# f28p65x_clb_logic_config_regs register map
Vendor: Texas Instruments
Peripheral module from a debugger description file (folder C2000).
Address unit: 16 bits
Registers are 32-bit, read-write, no defined reset value unless marked. A register's access mark holds for its fields unless they carry their own. Offsets are as the file gives them; lines under a group give offsets from that group; [hi:lo] are bit positions; {n}, {i} and the like mark numbered series; 'fields as' and 'values as' point back to an identical list; <NAME> marks a mode.

## CLB_LOGIC_CONFIG_REGS — CLB LOGIC CONFIG Registers
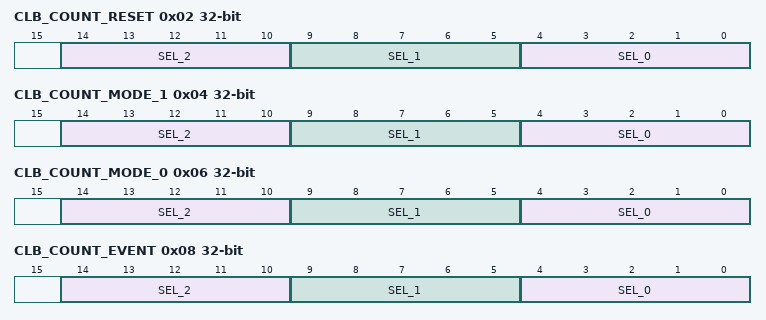
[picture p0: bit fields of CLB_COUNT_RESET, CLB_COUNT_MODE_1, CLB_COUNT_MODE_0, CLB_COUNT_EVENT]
0x02 CLB_COUNT_RESET — Counter Block RESET
  [14:10] SEL_2 — Count Reset Select 2
  [9:5] SEL_1 — Count Reset Select 1
  [4:0] SEL_0 — Count Reset Select 0
0x04 CLB_COUNT_MODE_1 — Counter Block MODE_1
  [14:10] SEL_2 — Counter mode 1 select 2
  [9:5] SEL_1 — Counter mode 1 select 1
  [4:0] SEL_0 — Counter mode 1 select 0
0x06 CLB_COUNT_MODE_0 — Counter Block MODE_0
  [14:10] SEL_2 — Counter mode 0 select 2
  [9:5] SEL_1 — Counter mode 0 select 1
  [4:0] SEL_0 — Counter mode 0 select 0
0x08 CLB_COUNT_EVENT — Counter Block EVENT
  [14:10] SEL_2 — Counter event select 2
  [9:5] SEL_1 — Counter event select 1
  [4:0] SEL_0 — Counter event select 0
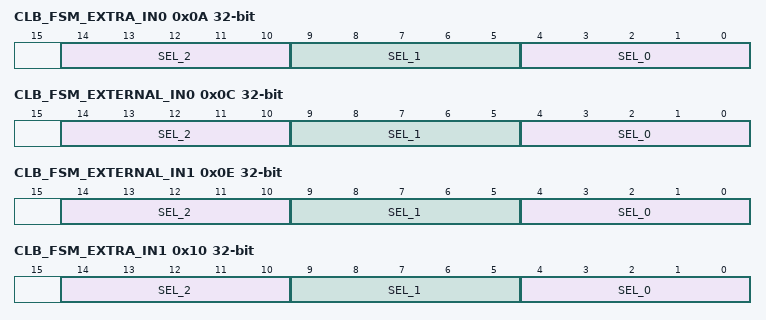
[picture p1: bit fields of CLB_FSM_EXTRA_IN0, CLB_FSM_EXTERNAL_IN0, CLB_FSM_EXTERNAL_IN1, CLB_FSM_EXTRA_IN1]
0x0A CLB_FSM_EXTRA_IN0 — FSM Extra EXT_IN0
  [14:10] SEL_2 — FSM extra ext input select 2
  [9:5] SEL_1 — FSM extra ext input select 1
  [4:0] SEL_0 — FSM extra ext input select 0
0x0C CLB_FSM_EXTERNAL_IN0 — FSM EXT_IN0
  [14:10] SEL_2 — FSM EXT_IN0 select input for unit 2
  [9:5] SEL_1 — FSM EXT_IN0 select input for unit 1
  [4:0] SEL_0 — FSM EXT_IN0 select input for unit 0
0x0E CLB_FSM_EXTERNAL_IN1 — FSM_EXT_IN1
  [14:10] SEL_2 — FSM EXT_IN1 select input for unit 2
  [9:5] SEL_1 — FSM EXT_IN1 select input for unit 1
  [4:0] SEL_0 — FSM EXT_IN1 select input for unit 0
0x10 CLB_FSM_EXTRA_IN1 — FSM Extra_EXT_IN1
  fields as CLB_FSM_EXTRA_IN0
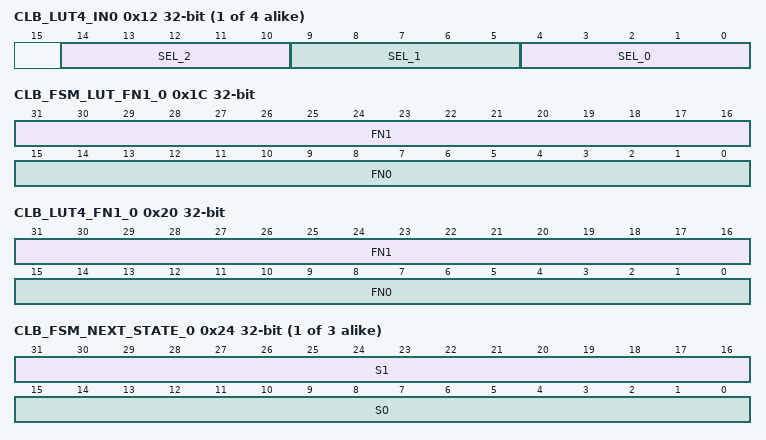
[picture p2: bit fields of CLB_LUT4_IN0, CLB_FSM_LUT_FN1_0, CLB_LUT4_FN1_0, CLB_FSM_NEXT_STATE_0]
{0x12+2i} CLB_LUT4_IN{i} (i=0..3) — LUT4_0/1/2 IN{i} input source
  [14:10] SEL_2 — Select inputs for unit 2
  [9:5] SEL_1 — Select inputs for unit 1
  [4:0] SEL_0 — Select inputs for unit 0
0x1C CLB_FSM_LUT_FN1_0 — LUT function for FSM Unit 1 and Unit 0
  [31:16] FN1 — FSM LUT output function for unit 1
  [15:0] FN0 — FSM LUT output function for unit 0
0x1E CLB_FSM_LUT_FN2 — LUT function for FSM Unit 2
  [15:0] FN1 — FSM LUT output function for unit 2
0x20 CLB_LUT4_FN1_0 — LUT function for LUT4 block of Unit 1 and 0
  [31:16] FN1 — LUT4 output function for unit 1
  [15:0] FN0 — LUT4 output function for unit 0
0x22 CLB_LUT4_FN2 — LUT function for LUT4 block of Unit 2
  [15:0] FN1 — LUT4 output function for unit 2
{0x24+2i} CLB_FSM_NEXT_STATE_{i} (i=0..2) — FSM Next state equations for Unit {i}
  [31:16] S1 — FSM next state function for S1
  [15:0] S0 — FSM next state function for S0
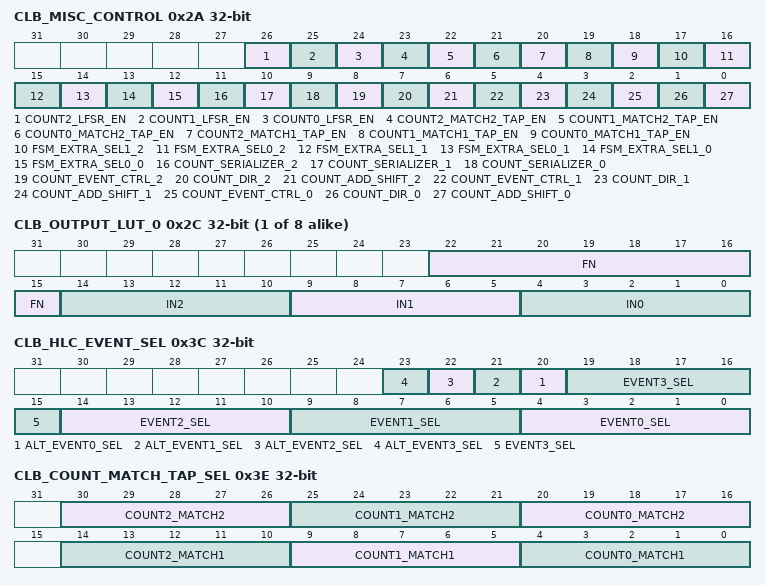
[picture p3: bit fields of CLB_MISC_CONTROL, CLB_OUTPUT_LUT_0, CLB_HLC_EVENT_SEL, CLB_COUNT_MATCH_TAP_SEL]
0x2A CLB_MISC_CONTROL — Static controls for Ctr,FSM
  [26] COUNT2_LFSR_EN — Enable LFSR mode for Counter 2
  [25] COUNT1_LFSR_EN — Enable LFSR mode for Counter 1
  [24] COUNT0_LFSR_EN — Enable LFSR mode for Counter 0
  [23] COUNT2_MATCH2_TAP_EN — Match2 Tap Enable for Counter 2
  [22] COUNT1_MATCH2_TAP_EN — Match2 Tap Enable for Counter 1
  [21] COUNT0_MATCH2_TAP_EN — Match2 Tap Enable for Counter 0
  [20] COUNT2_MATCH1_TAP_EN — Match1 Tap Enable for Counter 2
  [19] COUNT1_MATCH1_TAP_EN — Match1 Tap Enable for Counter 1
  [18] COUNT0_MATCH1_TAP_EN — Match1 Tap Enable for Counter 0
  [17] FSM_EXTRA_SEL1_2 — FSM extra_sel1 for 2
  [16] FSM_EXTRA_SEL0_2 — FSM extra_sel0 for 2
  [15] FSM_EXTRA_SEL1_1 — FSM extra_sel1 for 1
  [14] FSM_EXTRA_SEL0_1 — FSM extra_sel0 for 1
  [13] FSM_EXTRA_SEL1_0 — FSM extra_sel1 for 0
  [12] FSM_EXTRA_SEL0_0 — FSM extra_sel0 for 0
  [11] COUNT_SERIALIZER_2 — Serializer enable 2
  [10] COUNT_SERIALIZER_1 — Serializer enable 1
  [9] COUNT_SERIALIZER_0 — Serializer enable 0
  [8] COUNT_EVENT_CTRL_2 — Event control for counter 2
  [7] COUNT_DIR_2 — Direction for counter 2
  [6] COUNT_ADD_SHIFT_2 — Add/Shift for counter 2
  [5] COUNT_EVENT_CTRL_1 — Event control for counter 1
  [4] COUNT_DIR_1 — Direction for counter 1
  [3] COUNT_ADD_SHIFT_1 — Add/Shift for counter 1
  [2] COUNT_EVENT_CTRL_0 — Event control for counter 0
  [1] COUNT_DIR_0 — Direction for counter 0
  [0] COUNT_ADD_SHIFT_0 — Add/Shift for counter 0
{0x2C+2i} CLB_OUTPUT_LUT_{i} (i=0..7) — Inp Sel, LUT fns for Out{i}
  [22:15] FN — Output function for output LUT
  [14:10] IN2 — Select value for IN2 of output LUT
  [9:5] IN1 — Select value for IN1 of output LUT
  [4:0] IN0 — Select value for IN0 of output LUT
0x3C CLB_HLC_EVENT_SEL — Event Selector register for the High Level controller
  [n+20] ALT_EVENT{n}_SEL (n=0..3) — Event Select 3
  [5n+4:5n] EVENT{n}_SEL (n=0..3) — Event Select {n}
0x3E CLB_COUNT_MATCH_TAP_SEL — Counter tap values for match1 and match2 outputs
  [30:26] COUNT2_MATCH2 — Match2 tap select for Counter 2
  [25:21] COUNT1_MATCH2 — Match2 tap select for Counter 1
  [20:16] COUNT0_MATCH2 — Match2 tap select for Counter 0
  [14:10] COUNT2_MATCH1 — Match1 tap select for Counter 2
  [9:5] COUNT1_MATCH1 — Match1 tap select for Counter 1
  [4:0] COUNT0_MATCH1 — Match1 tap select for Counter 0
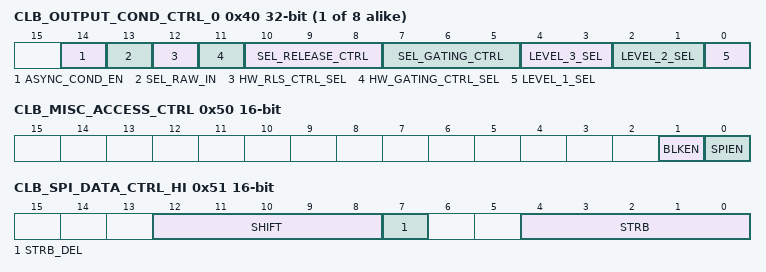
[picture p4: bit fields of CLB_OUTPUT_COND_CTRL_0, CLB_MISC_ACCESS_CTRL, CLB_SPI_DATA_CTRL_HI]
{0x40+2i} CLB_OUTPUT_COND_CTRL_{i} (i=0..7) — Output conditioning control for output {i}
  [14] ASYNC_COND_EN — Enable for conditioning
  [13] SEL_RAW_IN — Select input mode for the CLB AOC
  [12] HW_RLS_CTRL_SEL — Select HW for release control
  [11] HW_GATING_CTRL_SEL — Select HW for gating control
  [10:8] SEL_RELEASE_CTRL — Releast control mux select
  [7:5] SEL_GATING_CTRL — Gating control mux select
  [4:3] LEVEL_3_SEL — Level 3 Mux Select
  [2:1] LEVEL_2_SEL — Level 2 Mux Select
  [0] LEVEL_1_SEL — Level 1 Mux Select
0x50 CLB_MISC_ACCESS_CTRL 16-bit — Miscellaneous Access and enable control
  [1] BLKEN — Block Register write
  [0] SPIEN — Enable CLB SPI Buffer feature
0x51 CLB_SPI_DATA_CTRL_HI 16-bit — CLB to SPI buffer control High
  [12:8] SHIFT — Shift value select
  [7] STRB_DEL — Strobe delay enable
  [4:0] STRB — Select value for strobe
